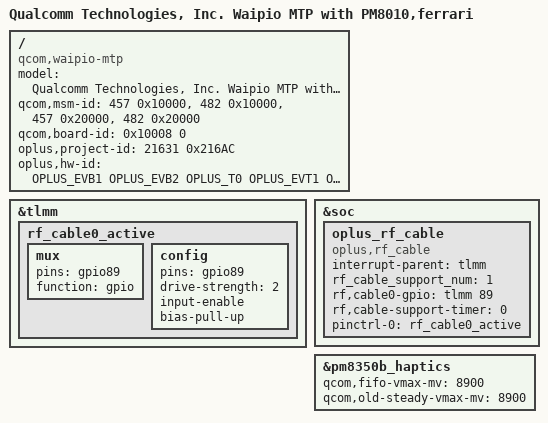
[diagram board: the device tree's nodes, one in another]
/dts-v1/;
/plugin/;

#include "../qcom/waipio-mtp.dtsi"

#include <dt-bindings/oplus/hw-id.h>
//#include "../qcom/waipio-mtp-pm8010-overlay.dts"
#include "waipio_overlay_common.dtsi"
#include "ferrari_21631_overlay_common.dtsi"
#include "oplus_chg/oplus-chg-21631.dtsi"
#include "nfc/ferrari-nfc-sn100t.dtsi"
#include "sensor/ferrari-oplus-sensor.dtsi"

/ {
    model = "Qualcomm Technologies, Inc. Waipio MTP with PM8010,ferrari";
    compatible = "qcom,waipio-mtp", "qcom,waipio", "qcom,mtp";
    qcom,msm-id = <457 0x10000>, <482 0x10000>, <457 0x20000>, <482 0x20000>;
    qcom,board-id = <0x10008 0>;

    oplus,project-id = <21631 0x216AC>;
    oplus,hw-id = <OPLUS_EVB1 OPLUS_EVB2 OPLUS_T0 OPLUS_EVT1 OPLUS_EVT2 OPLUS_EVT3 OPLUS_DVT1 OPLUS_DVT2 OPLUS_DVT3 OPLUS_PVT1 OPLUS_MP1 OPLUS_MP2 OPLUS_MP3>;
};

&tlmm {
  rf_cable0_active: rf_cable0_active {
    mux {
      pins = "gpio89";
      function = "gpio";
    };
    config {
      pins = "gpio89";
      drive-strength = <2>;
      input-enable;
      bias-pull-up;
    };
  };
};

&soc {
  oplus_rf_cable {
    compatible = "oplus,rf_cable";
    interrupt-parent = <&tlmm>;
    rf_cable_support_num = <1>;
    rf,cable0-gpio = <&tlmm 89 0>;
    rf,cable-support-timer = <0>;
    pinctrl-names = "rf_cable_active";
    pinctrl-0 = <&rf_cable0_active>;
  };
};
//#ifdef OPLUS_FEATURE_CHG_BASIC
&pm8350b_haptics {
    qcom,fifo-vmax-mv = <8900>;
    qcom,old-steady-vmax-mv = <8900>;//8.9v
};
//#endif

